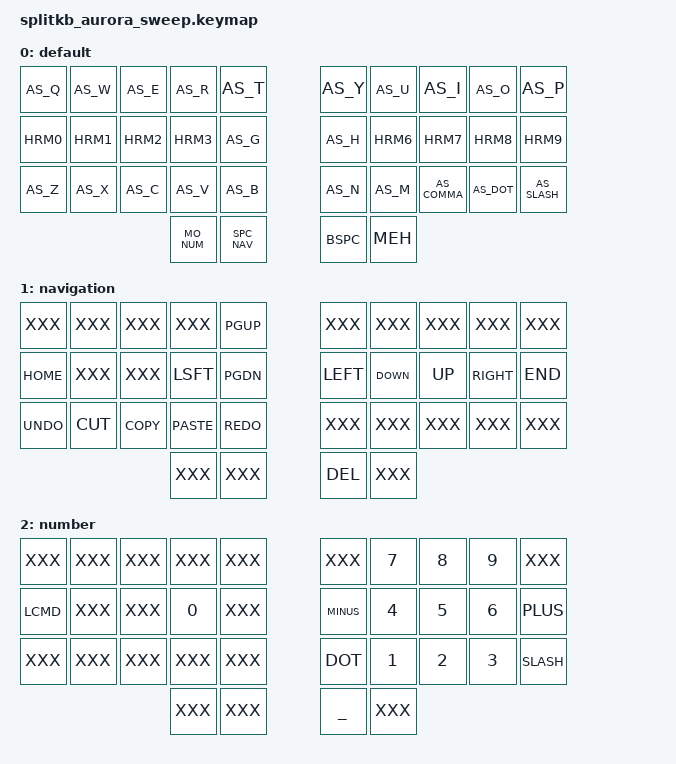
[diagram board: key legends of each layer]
/*
 * Copyright (c) 2022 The ZMK Contributors
 *
 * SPDX-License-Identifier: MIT
 */

#include <behaviors.dtsi>
#include <dt-bindings/zmk/keys.h>
#include <dt-bindings/zmk/bt.h>

#include "34_labels.h"
// #include "italian_keys.h"

#include "aliases.dtsi"
#include "helpers.dtsi"

/ {
     combos {
        compatible = "zmk,combos";
        #include "combos.dtsi"
     };

     behaviors {
          #include "hrm_as.dtsi"
     };
     
     keymap {
          compatible = "zmk,keymap";

          default {
               bindings = <
               // ╭─────────────┬─────────────┬─────────────┬─────────────┬─────────────╮   ╭─────────────┬─────────────┬─────────────┬─────────────┬─────────────╮
                    AS_Q          AS_W          AS_E          AS_R          AS_T              AS_Y          AS_U          AS_I          AS_O          AS_P
               // ├─────────────┼─────────────┼─────────────┼─────────────┼─────────────┤   ├─────────────┼─────────────┼─────────────┼─────────────┼─────────────┤
                    HRM0          HRM1          HRM2          HRM3          AS_G              AS_H          HRM6          HRM7          HRM8          HRM9          
               // ├─────────────┼─────────────┼─────────────┼─────────────┼─────────────┤   ├─────────────┼─────────────┼─────────────┼─────────────┼─────────────┤
                    AS_Z          AS_X          AS_C          AS_V          AS_B              AS_N          AS_M          AS_COMMA      AS_DOT        AS_SLASH
               // ╰─────────────┼─────────────┼─────────────┼─────────────┼─────────────┤   ├─────────────┼─────────────┼─────────────┼─────────────┼─────────────╯
                                                              MO_NUM        SPC_NAV           _BSPC         _MEH       
               //                                           ╰─────────────┴─────────────╯   ╰─────────────┴─────────────╯
               >;
          };

          navigation {
               bindings = <
               // ╭─────────────┬─────────────┬─────────────┬─────────────┬─────────────╮   ╭─────────────┬─────────────┬─────────────┬─────────────┬─────────────╮
                    XXX           XXX           XXX           XXX           _PGUP             XXX           XXX           XXX           XXX           XXX
               // ├─────────────┼─────────────┼─────────────┼─────────────┼─────────────┤   ├─────────────┼─────────────┼─────────────┼─────────────┼─────────────┤
                    _HOME         XXX           XXX           _LSFT         _PGDN             _LEFT         _DOWN         _UP           _RIGHT        _END
               // ├─────────────┼─────────────┼─────────────┼─────────────┼─────────────┤   ├─────────────┼─────────────┼─────────────┼─────────────┼─────────────┤
                    _UNDO         _CUT          _COPY         _PASTE        _REDO             XXX           XXX           XXX           XXX           XXX
               // ╰─────────────┼─────────────┼─────────────┼─────────────┼─────────────┤   ├─────────────┼─────────────┼─────────────┼─────────────┼─────────────╯
                                                              XXX           XXX               _DEL          XXX       
               //                                           ╰─────────────┴─────────────╯   ╰─────────────┴─────────────╯
               >;
          };

          number {
               bindings = <
               // ╭─────────────┬─────────────┬─────────────┬─────────────┬─────────────╮   ╭─────────────┬─────────────┬─────────────┬─────────────┬─────────────╮
                    XXX           XXX           XXX           XXX           XXX               XXX           _7            _8            _9            XXX
               // ├─────────────┼─────────────┼─────────────┼─────────────┼─────────────┤   ├─────────────┼─────────────┼─────────────┼─────────────┼─────────────┤
                    _LCMD         XXX           XXX           _0            XXX               _MINUS        _4            _5            _6            _PLUS
               // ├─────────────┼─────────────┼─────────────┼─────────────┼─────────────┤   ├─────────────┼─────────────┼─────────────┼─────────────┼─────────────┤
                    XXX           XXX           XXX           XXX           XXX               _DOT          _1            _2            _3            _SLASH
               // ╰─────────────┼─────────────┼─────────────┼─────────────┼─────────────┤   ├─────────────┼─────────────┼─────────────┼─────────────┼─────────────╯
                                                              XXX           XXX               ___           XXX       
               //                                           ╰─────────────┴─────────────╯   ╰─────────────┴─────────────╯
               >;
          };
     };
};
